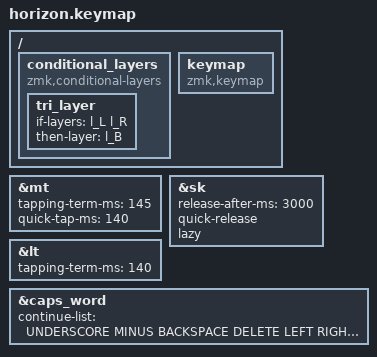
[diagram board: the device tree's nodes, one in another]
/*
 * Copyright (c) 2021 The ZMK Contributors
 *
 * SPDX-License-Identifier: MIT
 */

#include <behaviors.dtsi>
#include <dt-bindings/zmk/keys.h>
#include <dt-bindings/zmk/bt.h>
#include <dt-bindings/zmk/outputs.h>

#define l_ALPHA 0
#define l_HD 1
#define l_HD_CODE 2
#define l_L  3
#define l_R  4
#define l_B  5
#define l_G1 6
#define l_G2 7


&mt {
    tapping-term-ms = <145>;
    quick-tap-ms = <140>;
};

&sk {
    release-after-ms = <3000>;
    quick-release;
    lazy;
};

&lt {
    tapping-term-ms = <140>;
};


&caps_word {
        continue-list = <UNDERSCORE MINUS BACKSPACE DELETE LEFT RIGHT LS(FSLH) FSLH>;
    };

/{
    conditional_layers {
        compatible = "zmk,conditional-layers";
        tri_layer {
            if-layers = <l_L l_R>;
            then-layer = <l_B>;
        };
    };
    
    #define AS(keycode) &as LS(keycode) keycode     // Autoshift Macro

    #include "horizon_layout.dtsi"
    #include "behaviors.dtsi"    
    #include "macros.dtsi"
    #include "combos.dtsi"

        keymap {
            compatible = "zmk,keymap";
            #include "horizon_layers.dtsi"
    };
};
